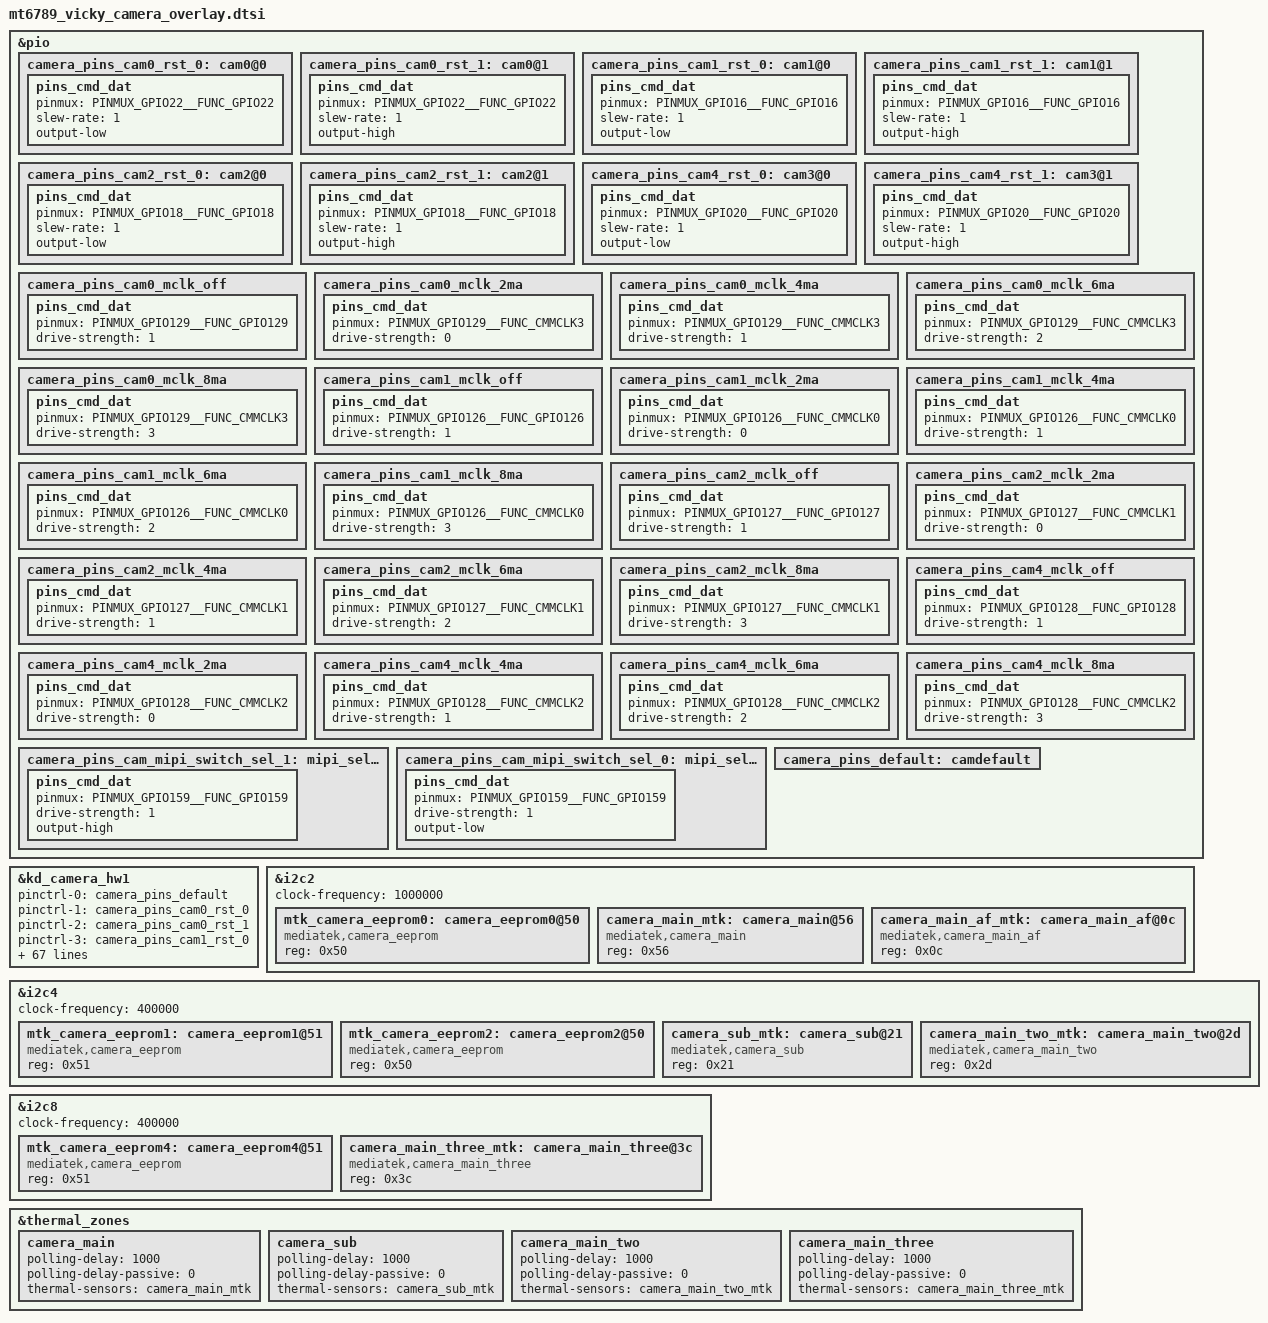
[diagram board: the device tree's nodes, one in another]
// SPDX-License-Identifier: GPL-2.0
/* Copyright (c) 2020 MediaTek Inc. */
/* CAMERA GPIO standardization */
&pio {
	camera_pins_cam0_rst_0: cam0@0 {
		pins_cmd_dat {
			pinmux = <PINMUX_GPIO22__FUNC_GPIO22>;
			slew-rate = <1>;
			output-low;
		};
	};
	camera_pins_cam0_rst_1: cam0@1 {
		pins_cmd_dat {
			pinmux = <PINMUX_GPIO22__FUNC_GPIO22>;
			slew-rate = <1>;
			output-high;
		};
	};
	camera_pins_cam1_rst_0: cam1@0 {
		pins_cmd_dat {
			pinmux = <PINMUX_GPIO16__FUNC_GPIO16>;
			slew-rate = <1>;
			output-low;
		};
	};
	camera_pins_cam1_rst_1: cam1@1 {
		pins_cmd_dat {
			pinmux = <PINMUX_GPIO16__FUNC_GPIO16>;
			slew-rate = <1>;
			output-high;
		};
	};
	camera_pins_cam2_rst_0: cam2@0 {
		pins_cmd_dat {
			pinmux = <PINMUX_GPIO18__FUNC_GPIO18>;
			slew-rate = <1>;
			output-low;
		};
	};
	camera_pins_cam2_rst_1: cam2@1 {
		pins_cmd_dat {
			pinmux = <PINMUX_GPIO18__FUNC_GPIO18>;
			slew-rate = <1>;
			output-high;
		};
	};
	camera_pins_cam4_rst_0: cam3@0 {
		pins_cmd_dat {
			pinmux = <PINMUX_GPIO20__FUNC_GPIO20>;
			slew-rate = <1>;
			output-low;
		};
	};
	camera_pins_cam4_rst_1: cam3@1 {
		pins_cmd_dat {
			pinmux = <PINMUX_GPIO20__FUNC_GPIO20>;
			slew-rate = <1>;
			output-high;
		};
	};
	camera_pins_cam0_mclk_off: camera_pins_cam0_mclk_off {
		pins_cmd_dat {
			pinmux = <PINMUX_GPIO129__FUNC_GPIO129>;
			drive-strength = <1>;
		};
	};
	camera_pins_cam0_mclk_2ma: camera_pins_cam0_mclk_2ma {
		pins_cmd_dat {
			pinmux = <PINMUX_GPIO129__FUNC_CMMCLK3>;
			drive-strength = <0>;
		};
	};
	camera_pins_cam0_mclk_4ma: camera_pins_cam0_mclk_4ma {
		pins_cmd_dat {
			pinmux = <PINMUX_GPIO129__FUNC_CMMCLK3>;
			drive-strength = <1>;
		};
	};
	camera_pins_cam0_mclk_6ma: camera_pins_cam0_mclk_6ma {
		pins_cmd_dat {
			pinmux = <PINMUX_GPIO129__FUNC_CMMCLK3>;
			drive-strength = <2>;
		};
	};
	camera_pins_cam0_mclk_8ma: camera_pins_cam0_mclk_8ma {
		pins_cmd_dat {
			pinmux = <PINMUX_GPIO129__FUNC_CMMCLK3>;
			drive-strength = <3>;
		};
	};
	camera_pins_cam1_mclk_off: camera_pins_cam1_mclk_off {
		pins_cmd_dat {
			pinmux = <PINMUX_GPIO126__FUNC_GPIO126>;
			drive-strength = <1>;
		};
	};
	camera_pins_cam1_mclk_2ma: camera_pins_cam1_mclk_2ma {
		pins_cmd_dat {
			pinmux = <PINMUX_GPIO126__FUNC_CMMCLK0>;
			drive-strength = <0>;
		};
	};
	camera_pins_cam1_mclk_4ma: camera_pins_cam1_mclk_4ma {
		pins_cmd_dat {
			pinmux = <PINMUX_GPIO126__FUNC_CMMCLK0>;
			drive-strength = <1>;
		};
	};
	camera_pins_cam1_mclk_6ma: camera_pins_cam1_mclk_6ma {
		pins_cmd_dat {
			pinmux = <PINMUX_GPIO126__FUNC_CMMCLK0>;
			drive-strength = <2>;
		};
	};
	camera_pins_cam1_mclk_8ma: camera_pins_cam1_mclk_8ma {
		pins_cmd_dat {
			pinmux = <PINMUX_GPIO126__FUNC_CMMCLK0>;
			drive-strength = <3>;
		};
	};
	camera_pins_cam2_mclk_off: camera_pins_cam2_mclk_off {
		pins_cmd_dat {
			pinmux = <PINMUX_GPIO127__FUNC_GPIO127>;
			drive-strength = <1>;
		};
	};
	camera_pins_cam2_mclk_2ma: camera_pins_cam2_mclk_2ma {
		pins_cmd_dat {
			pinmux = <PINMUX_GPIO127__FUNC_CMMCLK1>;
			drive-strength = <0>;
		};
	};
	camera_pins_cam2_mclk_4ma: camera_pins_cam2_mclk_4ma {
		pins_cmd_dat {
			pinmux = <PINMUX_GPIO127__FUNC_CMMCLK1>;
			drive-strength = <1>;
		};
	};
	camera_pins_cam2_mclk_6ma: camera_pins_cam2_mclk_6ma {
		pins_cmd_dat {
			pinmux = <PINMUX_GPIO127__FUNC_CMMCLK1>;
			drive-strength = <2>;
		};
	};
	camera_pins_cam2_mclk_8ma: camera_pins_cam2_mclk_8ma {
		pins_cmd_dat {
			pinmux = <PINMUX_GPIO127__FUNC_CMMCLK1>;
			drive-strength = <3>;
		};
	};
	camera_pins_cam4_mclk_off: camera_pins_cam4_mclk_off {
		pins_cmd_dat {
			pinmux = <PINMUX_GPIO128__FUNC_GPIO128>;
			drive-strength = <1>;
		};
	};
	camera_pins_cam4_mclk_2ma: camera_pins_cam4_mclk_2ma {
		pins_cmd_dat {
			pinmux = <PINMUX_GPIO128__FUNC_CMMCLK2>;
			drive-strength = <0>;
		};
	};
	camera_pins_cam4_mclk_4ma: camera_pins_cam4_mclk_4ma {
		pins_cmd_dat {
			pinmux = <PINMUX_GPIO128__FUNC_CMMCLK2>;
			drive-strength = <1>;
		};
	};
	camera_pins_cam4_mclk_6ma: camera_pins_cam4_mclk_6ma {
		pins_cmd_dat {
			pinmux = <PINMUX_GPIO128__FUNC_CMMCLK2>;
			drive-strength = <2>;
		};
	};
	camera_pins_cam4_mclk_8ma: camera_pins_cam4_mclk_8ma {
		pins_cmd_dat {
			pinmux = <PINMUX_GPIO128__FUNC_CMMCLK2>;
			drive-strength = <3>;
		};
	};

	camera_pins_cam_mipi_switch_sel_1: mipi_sel@1 {
		pins_cmd_dat {
			pinmux = <PINMUX_GPIO159__FUNC_GPIO159>;
			drive-strength = <1>;
			output-high;
		};
	};

	camera_pins_cam_mipi_switch_sel_0: mipi_sel@0 {
		pins_cmd_dat {
			pinmux = <PINMUX_GPIO159__FUNC_GPIO159>;
			drive-strength = <1>;
			output-low;
		};
	};

	camera_pins_default: camdefault {
	};
};
&kd_camera_hw1 {
	pinctrl-names = "default",
			"cam0_rst0", "cam0_rst1",
			"cam1_rst0", "cam1_rst1",
			"cam2_rst0", "cam2_rst1",
			"cam4_rst0", "cam4_rst1",
			"cam0_mclk_off",
			"cam0_mclk_2mA", "cam0_mclk_4mA",
			"cam0_mclk_6mA", "cam0_mclk_8mA",
			"cam1_mclk_off",
			"cam1_mclk_2mA", "cam1_mclk_4mA",
			"cam1_mclk_6mA", "cam1_mclk_8mA",
			"cam2_mclk_off",
			"cam2_mclk_2mA", "cam2_mclk_4mA",
			"cam2_mclk_6mA", "cam2_mclk_8mA",
			"cam4_mclk_off",
			"cam4_mclk_2mA", "cam4_mclk_4mA",
			"cam4_mclk_6mA", "cam4_mclk_8mA",
			"cam_mipi_switch_sel_1", "cam_mipi_switch_sel_0";

	pinctrl-0 = <&camera_pins_default>;
	pinctrl-1 = <&camera_pins_cam0_rst_0>;
	pinctrl-2 = <&camera_pins_cam0_rst_1>;
	pinctrl-3 = <&camera_pins_cam1_rst_0>;
	pinctrl-4 = <&camera_pins_cam1_rst_1>;
	pinctrl-5 = <&camera_pins_cam2_rst_0>;
	pinctrl-6 = <&camera_pins_cam2_rst_1>;
	pinctrl-7 = <&camera_pins_cam4_rst_0>;
	pinctrl-8 = <&camera_pins_cam4_rst_1>;
	pinctrl-9 = <&camera_pins_cam0_mclk_off>;
	pinctrl-10 = <&camera_pins_cam0_mclk_2ma>;
	pinctrl-11= <&camera_pins_cam0_mclk_4ma>;
	pinctrl-12 = <&camera_pins_cam0_mclk_6ma>;
	pinctrl-13 = <&camera_pins_cam0_mclk_8ma>;
	pinctrl-14 = <&camera_pins_cam1_mclk_off>;
	pinctrl-15 = <&camera_pins_cam1_mclk_2ma>;
	pinctrl-16 = <&camera_pins_cam1_mclk_4ma>;
	pinctrl-17 = <&camera_pins_cam1_mclk_6ma>;
	pinctrl-18 = <&camera_pins_cam1_mclk_8ma>;
	pinctrl-19 = <&camera_pins_cam2_mclk_off>;
	pinctrl-20 = <&camera_pins_cam2_mclk_2ma>;
	pinctrl-21 = <&camera_pins_cam2_mclk_4ma>;
	pinctrl-22 = <&camera_pins_cam2_mclk_6ma>;
	pinctrl-23 = <&camera_pins_cam2_mclk_8ma>;
	pinctrl-24 = <&camera_pins_cam4_mclk_off>;
	pinctrl-25 = <&camera_pins_cam4_mclk_2ma>;
	pinctrl-26 = <&camera_pins_cam4_mclk_4ma>;
	pinctrl-27 = <&camera_pins_cam4_mclk_6ma>;
	pinctrl-28 = <&camera_pins_cam4_mclk_8ma>;
	pinctrl-29 = <&camera_pins_cam_mipi_switch_sel_1>;
	pinctrl-30 = <&camera_pins_cam_mipi_switch_sel_0>;

	/* main hm6*/
	cam0_vcama-supply = <&mt6358_vcamio_reg>;
	cam0_vcamio-supply = <&mt6358_vcamio_reg>;
	cam0_vcamd-supply = <&mt6358_vcamio_reg>;
	cam0_vcamaf-supply = <&mt6358_vcamio_reg>;

	/* front hi1634*/
	cam1_vcama-supply = <&mt6358_vcamio_reg>;
	cam1_vcamio-supply = <&mt6358_vcamio_reg>;
	cam1_vcamd-supply = <&mt6358_vcamio_reg>;

	/* main2 s5k4h7*/
	cam2_vcama-supply = <&mt6358_vcamio_reg>;
	cam2_vcamio-supply = <&mt6358_vcamio_reg>;
	cam2_vcamd-supply = <&mt6358_vcamio_reg>;

	/*main3 ov02b10*/
	cam4_vcamio-supply = <&mt6358_vcamio_reg>;
	cam4_vcama-supply = <&mt6358_vcamio_reg>;

	cam0_pin_mclk = "mclk";
	cam0_pin_rst = "gpio";
	cam0_pin_vcama = "wl2868";
	cam0_pin_vcamio = "wl2868";
	cam0_pin_vcamd = "wl2868";
	cam0_pin_vcamaf = "wl2868";
	cam1_pin_mclk = "mclk";
	cam1_pin_rst = "gpio";
	cam1_pin_vcama = "wl2868";
	cam1_pin_vcamio = "wl2868";
	cam1_pin_vcamd = "wl2868";
	cam1_pin_vcama1 = "regulator";
	cam2_pin_mclk = "mclk";
	cam2_pin_rst = "gpio";
	cam2_pin_vcama = "wl2868";
	cam2_pin_vcamio = "wl2868";
	cam2_pin_vcamd = "wl2868";
	//cam2_pin_vcama1 = "regulator";
	cam1_pin_mipi_switch_sel = "gpio";
	cam2_pin_mipi_switch_sel = "gpio";

	cam4_pin_mclk = "mclk";
	cam4_pin_rst = "gpio";
	cam4_pin_vcama = "wl2868";
	cam4_pin_vcamio = "wl2868";
	cam0_enable_sensor = "mot_vicky_s5khm6_mipi_raw mot_vicky_s5kgm1_mipi_raw";

	cam1_enable_sensor = "mot_vicky_hi1634q_mipi_raw";
	cam2_enable_sensor = "mot_vicky_s5k4h7_mipi_raw";
	cam4_enable_sensor = "mot_vicky_ov02b10_mipi_raw";
	status = "okay";
};
/* CAMERA GPIO end */

/* CAMERA EEPROM */
&i2c2 {
	status = "okay";
	clock-frequency = <1000000>;
	#address-cells = <1>;
	#size-cells = <0>;

	mtk_camera_eeprom0:camera_eeprom0@50 {
		compatible = "mediatek,camera_eeprom";
		reg = <0x50>;
		status = "okay";
	};

	/*hm6*/
	camera_main_mtk:camera_main@56 {
		compatible = "mediatek,camera_main";
		#thermal-sensor-cells = <0>;
		reg = <0x56>;
		status = "okay";
	};

	camera_main_af_mtk:camera_main_af@0c {
		compatible = "mediatek,camera_main_af";
		reg = <0x0c>;
		status = "okay";
	};
};
&i2c4 {
	status = "okay";
	clock-frequency = <400000>;
	#address-cells = <1>;
	#size-cells = <0>;

	mtk_camera_eeprom1:camera_eeprom1@51 {
		compatible = "mediatek,camera_eeprom";
		reg = <0x51>;
		status = "okay";
	};
	mtk_camera_eeprom2:camera_eeprom2@50 {
		compatible = "mediatek,camera_eeprom";
		reg = <0x50>;
		status = "okay";
	};
        /*Hi1634Q*/
	camera_sub_mtk:camera_sub@21 {
		compatible = "mediatek,camera_sub";
		#thermal-sensor-cells = <0>;
		reg = <0x21>;
		status = "okay";
	};

	/*mot_vicky_s5k4h7*/
	camera_main_two_mtk:camera_main_two@2d {
		compatible = "mediatek,camera_main_two";
		#thermal-sensor-cells = <0>;
		reg = <0x2d>;
		status = "okay";
	};
};
&i2c8 {
	status = "okay";
	clock-frequency = <400000>;
	#address-cells = <1>;
	#size-cells = <0>;

	mtk_camera_eeprom4:camera_eeprom4@51 {
		compatible = "mediatek,camera_eeprom";
		reg = <0x51>;
		status = "okay";
	};

	/*mot_vicky_ov02b10*/
	camera_main_three_mtk:camera_main_three@3c {
		compatible = "mediatek,camera_main_three";
		#thermal-sensor-cells = <0>;
		reg = <0x3c>;
		status = "okay";
	};
};
/* CAMERA EEPROM end */

/* CAMERA TZ config */
&thermal_zones {
	camera_main: camera_main {
		polling-delay = <1000>; /* milliseconds */
		polling-delay-passive = <0>; /* milliseconds */
		thermal-sensors = <&camera_main_mtk>;
	};
	camera_sub: camera_sub {
		polling-delay = <1000>; /* milliseconds */
		polling-delay-passive = <0>; /* milliseconds */
		thermal-sensors = <&camera_sub_mtk>;
	};
	camera_main_two: camera_main_two {
		polling-delay = <1000>; /* milliseconds */
		polling-delay-passive = <0>; /* milliseconds */
		thermal-sensors = <&camera_main_two_mtk>;
	};
	camera_main_three: camera_main_three {
		polling-delay = <1000>; /* milliseconds */
		polling-delay-passive = <0>; /* milliseconds */
		thermal-sensors = <&camera_main_three_mtk>;
	};
};
/* CAMERA TZ config end */
